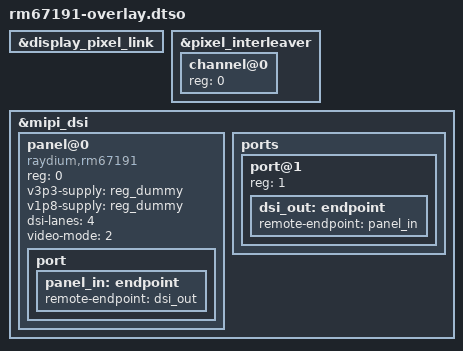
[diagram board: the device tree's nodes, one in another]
// SPDX-License-Identifier: GPL-2.0-or-later
/*
 * i.MX95 MIPI-DSI display overlay: a Raydium RM67191 DSI panel on the DPU's
 * pixel-link -> MIPI-DSI host path. Modelled on the BSP's
 * imx95-19x19-evk-dsi-serdes.dtso routing (display_pixel_link + pixel_interleaver
 * + mipi_dsi enabled), but with the max96789 serdes chain replaced by a direct
 * rm67191 DSI panel (a built-in panel driver, no firmware). The QEMU
 * imx95.dsi model answers the dw-mipi-dsi core's status polls so the bridge
 * enables and the panel's DSI init commands complete; the DPU model does the
 * scanout. The panel needs no reset GPIO or backlight phandle (both optional).
 */

/dts-v1/;
/plugin/;

&display_pixel_link {
	status = "okay";
};

&pixel_interleaver {
	#address-cells = <1>;
	#size-cells = <0>;
	status = "okay";

	channel@0 {
		reg = <0>;
		status = "okay";
	};
};

&mipi_dsi {
	#address-cells = <1>;
	#size-cells = <0>;
	status = "okay";

	panel@0 {
		compatible = "raydium,rm67191";
		reg = <0>;
		v3p3-supply = <&reg_dummy>;
		v1p8-supply = <&reg_dummy>;
		dsi-lanes = <4>;
		video-mode = <2>;

		port {
			panel_in: endpoint {
				remote-endpoint = <&dsi_out>;
			};
		};
	};

	ports {
		#address-cells = <1>;
		#size-cells = <0>;

		port@1 {
			reg = <1>;
			dsi_out: endpoint {
				remote-endpoint = <&panel_in>;
			};
		};
	};
};
